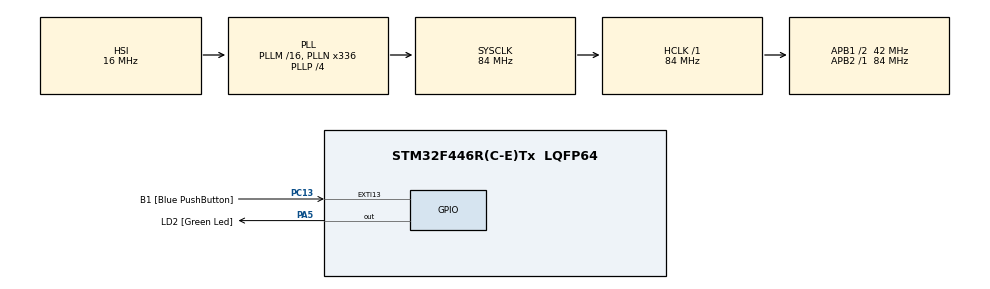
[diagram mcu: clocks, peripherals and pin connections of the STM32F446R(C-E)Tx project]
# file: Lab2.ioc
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Mcu.Family=STM32F4
Mcu.Name=STM32F446R(C-E)Tx
Mcu.Package=LQFP64
NVIC.EXTI15_10_IRQn=true\:0\:0\:false\:false\:true\:true\:true\:true
NVIC.PriorityGroup=NVIC_PRIORITYGROUP_0
PA13.GPIO_Label=TMS
PA13.Mode=Serial_Wire
PA13.Signal=SYS_JTMS-SWDIO
PA14.GPIO_Label=TCK
PA14.Mode=Serial_Wire
PA14.Signal=SYS_JTCK-SWCLK
PA2.GPIO_ModeDefaultPP=GPIO_MODE_AF_PP
PA2.GPIO_PuPd=GPIO_NOPULL
PA2.GPIO_Speed=GPIO_SPEED_FREQ_VERY_HIGH
PA2.Signal=USART2_TX
PA3.GPIO_ModeDefaultPP=GPIO_MODE_AF_PP
PA3.GPIO_PuPd=GPIO_NOPULL
PA3.GPIO_Speed=GPIO_SPEED_FREQ_VERY_HIGH
PA3.Signal=USART2_RX
PA5.GPIO_Label=LD2 [Green Led]
PA5.Signal=GPIO_Output
PB3.GPIO_Label=SWO
PB3.Signal=SYS_JTDO-SWO
PC13.GPIO_Label=B1 [Blue PushButton]
PC13.GPIO_ModeDefaultEXTI=GPIO_MODE_IT_FALLING
PC13.Signal=GPXTI13
PC14-OSC32_IN.Mode=LSE-External-Oscillator
PC14-OSC32_IN.Signal=RCC_OSC32_IN
PC15-OSC32_OUT.Mode=LSE-External-Oscillator
PC15-OSC32_OUT.Signal=RCC_OSC32_OUT
PH0-OSC_IN.Mode=HSE-External-Oscillator
PH0-OSC_IN.Signal=RCC_OSC_IN
PH1-OSC_OUT.Mode=HSE-External-Oscillator
PH1-OSC_OUT.Signal=RCC_OSC_OUT
ProjectManager.HeapSize=0x200
ProjectManager.StackSize=0x400
ProjectManager.TargetToolchain=CMake
RCC.48MHZClocksFreq_Value=84000000
RCC.AHBFreq_Value=84000000
RCC.APB1CLKDivider=RCC_HCLK_DIV2
RCC.APB1Freq_Value=42000000
RCC.APB1TimFreq_Value=84000000
RCC.APB2Freq_Value=84000000
RCC.APB2TimFreq_Value=84000000
RCC.CortexFreq_Value=84000000
RCC.FLatency-AdvancedSettings=FLASH_LATENCY_2
RCC.HCLKFreq_Value=84000000
RCC.HSE_VALUE=8000000
RCC.HSI_VALUE=16000000
RCC.PLLN=336
RCC.PLLP=RCC_PLLP_DIV4
RCC.SYSCLKFreq_VALUE=84000000
RCC.SYSCLKSource=RCC_SYSCLKSOURCE_PLLCLK
RCC.USBFreq_Value=168000000
RCC.VCOOutputFreq_Value=336000000
STMicroelectronics.X-CUBE-ALGOBUILD.1.4.0.LibraryCcDSPOoLibraryJjDSPOoLibrary=true
VP_STMicroelectronics.X-CUBE-ALGOBUILD_VS_DSPOoLibraryJjLibrary_1.4.0_1.4.0.Mode=DSPOoLibraryJjLibrary
board=NUCLEO-F446RE

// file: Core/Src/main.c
/* USER CODE BEGIN Header */
/**
 ******************************************************************************
 * @file           : main.c
 * @brief          : Main program body
 ******************************************************************************
 * @attention
 *
 * Copyright (c) 2026 STMicroelectronics.
 * All rights reserved.
 *
 * This software is licensed under terms that can be found in the LICENSE file
 * in the root directory of this software component.
 * If no LICENSE file comes with this software, it is provided AS-IS.
 *
 ******************************************************************************
 */
/* USER CODE END Header */
#include "main.h"
#include "arm_math.h"

/* USER CODE BEGIN PD */
#define FFT_LENGTH 2048
#define SAMPLING_RATE 16384

#define N_TAPS 32
#define N_BLOCK 32
/* USER CODE END PD */

/* USER CODE BEGIN PV */
float32_t input_signal[FFT_LENGTH];
float32_t output_fft[FFT_LENGTH];
float32_t input_fft_mag[FFT_LENGTH / 2];
float32_t filtered_fft_mag[FFT_LENGTH / 2];
float32_t output_freq[FFT_LENGTH / 2];
arm_rfft_fast_instance_f32 fft_handler;
float32_t filtered_signal[FFT_LENGTH];
float32_t State[N_TAPS + N_BLOCK - 1];

static float32_t Coeffs[N_TAPS] = {
    -0.004344147732779473,  -0.009168771306895345,  -0.009724726663831892,
    -0.014577553983187346,  -0.014952323254611453,  -0.014925558361240522,
    -0.01026561726418485,   -0.0024817460791642034, 0.010003390455751927,
    0.025902379839063516,   0.04482221705027414,    0.06486658161749063,
    0.08440325053709288,    0.10127458250446596,    0.11374001867323824,
    0.12034176639902075,    0.12034176639902075,    0.11374001867323824,
    0.10127458250446596,    0.08440325053709288,    0.06486658161749063,
    0.04482221705027414,    0.025902379839063516,   0.010003390455751927,
    -0.0024817460791642034, -0.01026561726418485,   -0.014925558361240522,
    -0.014952323254611453,  -0.014577553983187346,  -0.009724726663831892,
    -0.009168771306895345,  -0.004344147732779473};

arm_fir_instance_f32 filter1;
/* USER CODE END PV */

void SystemClock_Config(void);
static void MX_GPIO_Init(void);

int main(void) {
  HAL_Init();

  SystemClock_Config();

  /* Initialize all configured peripherals */
  MX_GPIO_Init();

  arm_rfft_fast_init_f32(&fft_handler, FFT_LENGTH);
  arm_fir_init_f32(&filter1, N_TAPS, &Coeffs[0], &State[0], N_BLOCK);

  for (int i = 0; i < FFT_LENGTH; i++)
    input_signal[i] = arm_cos_f32(2 * PI * 400 * i / SAMPLING_RATE) +
                      arm_cos_f32(2 * PI * 3140 * i / SAMPLING_RATE);

  for (int i = 0; i < FFT_LENGTH / 2; i++)
    output_freq[i] = (float32_t)(i) / FFT_LENGTH * SAMPLING_RATE;

  for (int i = 0; i < (FFT_LENGTH / N_BLOCK); i++) {
    arm_fir_f32(&filter1, &input_signal[i * N_BLOCK],
                &filtered_signal[i * N_BLOCK], N_BLOCK);
  }

  // arm_rfft_fast_f32(&fft_handler, input_signal, output_fft, 0);
  // arm_cmplx_mag_f32(output_fft, input_fft_mag, FFT_LENGTH / 2);
  //
  // arm_rfft_fast_f32(&fft_handler, filtered_signal, output_fft, 0);
  // arm_cmplx_mag_f32(output_fft, filtered_fft_mag, FFT_LENGTH / 2);

  /* Infinite loop */
  while (1) {
    HAL_Delay(1000);
  }
}

void SystemClock_Config(void) {
  RCC_OscInitTypeDef RCC_OscInitStruct = {0};
  RCC_ClkInitTypeDef RCC_ClkInitStruct = {0};

  /** Configure the main internal regulator output voltage
   */
  __HAL_RCC_PWR_CLK_ENABLE();
  __HAL_PWR_VOLTAGESCALING_CONFIG(PWR_REGULATOR_VOLTAGE_SCALE3);

  /** Initializes the RCC Oscillators according to the specified parameters
   * in the RCC_OscInitTypeDef structure.
   */
  RCC_OscInitStruct.OscillatorType = RCC_OSCILLATORTYPE_HSI;
  RCC_OscInitStruct.HSIState = RCC_HSI_ON;
  RCC_OscInitStruct.HSICalibrationValue = RCC_HSICALIBRATION_DEFAULT;
  RCC_OscInitStruct.PLL.PLLState = RCC_PLL_ON;
  RCC_OscInitStruct.PLL.PLLSource = RCC_PLLSOURCE_HSI;
  RCC_OscInitStruct.PLL.PLLM = 16;
  RCC_OscInitStruct.PLL.PLLN = 336;
  RCC_OscInitStruct.PLL.PLLP = RCC_PLLP_DIV4;
  RCC_OscInitStruct.PLL.PLLQ = 2;
  RCC_OscInitStruct.PLL.PLLR = 2;
  if (HAL_RCC_OscConfig(&RCC_OscInitStruct) != HAL_OK) {
    Error_Handler();
  }

  /** Initializes the CPU, AHB and APB buses clocks
   */
  RCC_ClkInitStruct.ClockType = RCC_CLOCKTYPE_HCLK | RCC_CLOCKTYPE_SYSCLK |
                                RCC_CLOCKTYPE_PCLK1 | RCC_CLOCKTYPE_PCLK2;
  RCC_ClkInitStruct.SYSCLKSource = RCC_SYSCLKSOURCE_PLLCLK;
  RCC_ClkInitStruct.AHBCLKDivider = RCC_SYSCLK_DIV1;
  RCC_ClkInitStruct.APB1CLKDivider = RCC_HCLK_DIV2;
  RCC_ClkInitStruct.APB2CLKDivider = RCC_HCLK_DIV1;

  if (HAL_RCC_ClockConfig(&RCC_ClkInitStruct, FLASH_LATENCY_2) != HAL_OK) {
    Error_Handler();
  }
}

static void MX_GPIO_Init(void) {
  GPIO_InitTypeDef GPIO_InitStruct = {0};

  /* GPIO Ports Clock Enable */
  __HAL_RCC_GPIOC_CLK_ENABLE();
  __HAL_RCC_GPIOH_CLK_ENABLE();
  __HAL_RCC_GPIOA_CLK_ENABLE();
  __HAL_RCC_GPIOB_CLK_ENABLE();

  /*Configure GPIO pin Output Level */
  HAL_GPIO_WritePin(LD2_GPIO_Port, LD2_Pin, GPIO_PIN_RESET);

  /*Configure GPIO pin : B1_Pin */
  GPIO_InitStruct.Pin = B1_Pin;
  GPIO_InitStruct.Mode = GPIO_MODE_IT_FALLING;
  GPIO_InitStruct.Pull = GPIO_NOPULL;
  HAL_GPIO_Init(B1_GPIO_Port, &GPIO_InitStruct);

  /*Configure GPIO pins : PA2 PA3 */
  GPIO_InitStruct.Pin = GPIO_PIN_2 | GPIO_PIN_3;
  GPIO_InitStruct.Mode = GPIO_MODE_AF_PP;
  GPIO_InitStruct.Pull = GPIO_NOPULL;
  GPIO_InitStruct.Speed = GPIO_SPEED_FREQ_VERY_HIGH;
  GPIO_InitStruct.Alternate = GPIO_AF7_USART2;
  HAL_GPIO_Init(GPIOA, &GPIO_InitStruct);

  /*Configure GPIO pin : LD2_Pin */
  GPIO_InitStruct.Pin = LD2_Pin;
  GPIO_InitStruct.Mode = GPIO_MODE_OUTPUT_PP;
  GPIO_InitStruct.Pull = GPIO_NOPULL;
  GPIO_InitStruct.Speed = GPIO_SPEED_FREQ_LOW;
  HAL_GPIO_Init(LD2_GPIO_Port, &GPIO_InitStruct);

  /* EXTI interrupt init*/
  HAL_NVIC_SetPriority(EXTI15_10_IRQn, 0, 0);
  HAL_NVIC_EnableIRQ(EXTI15_10_IRQn);

}

void Error_Handler(void) {
  __disable_irq();
  while (1) {
  }
}
